# CY8C5868AXI_LP035 register map
File version: 0.1
Registers are 8-bit, read-write, no defined reset value unless marked. A register's access mark holds for its fields unless they carry their own. Offsets are from the block's base; [hi:lo] are bit positions; {n}, {i} and the like mark numbered series; 'fields as' and 'values as' point back to an identical list.

## WaveDAC8_1_VDAC8
Base 0x400043A8
0x00 VDAC8_PM_ACT_CFG — Active Power Mode Configuration Register 8
  [4:0] en_dac — Enable DAC block(s). Populated subsystems are counted from the LSB
0x10 VDAC8_PM_STBY_CFG — Standby Power Mode Configuration Register 8
  fields as VDAC8_PM_ACT_CFG
0x261 VDAC8_TR
  [7:0] tr — 8 Calibration bits
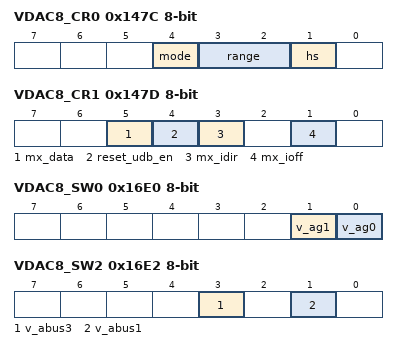
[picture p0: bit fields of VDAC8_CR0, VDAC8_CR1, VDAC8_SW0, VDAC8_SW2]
0x147C VDAC8_CR0 — DAC Block Control Register 0
  [4] mode ro — Mode Bit
    0=DAC_MODE_V (voltage DAC); 1=DAC_MODE_I (current DAC)
  [3:2] range — Ranges for mode=0 (VDAC) and mode=1 (IDAC)
    0=DAC_RANGE_0 (x0=0V to 4*vref (1.024V); 0 to 31.875uA); 1=DAC_RANGE_1 (x1=0V to 16*vref (4.096V); 0 to 255uA); 2=DAC_RANGE_2 (x0=0V to 4*vref (1.024V); 0 to 2.040mA); 3=DAC_RANGE_3 (x1=0V to 16*vref (4.096V); not used)
  [1] hs — High Speed Bit
    0=DAC_HS_LOWPOWER (regular (low power)); 1=DAC_HS_HIGHSPEED (high speed (higher power))
0x147D VDAC8_CR1 — DAC Block Control Register 1
  [5] mx_data — Select DATA source
    0=MX_DATA_REG (Select register source (DACxn_D)); 1=MX_DATA_UDB (Select UDB source)
  [4] reset_udb_en — DAC reset enable
    0=RESET_UDB_EN_DISABLE (Disable DAC Reset Source from UDB (System reset always resets)); 1=RESET_UDB_EN_ENABLE (Enable DAC Reset Source from UDB)
  [3] mx_idir — Mux selection for DAC current direction control
    0=MX_IDIR_REG (Register source idirbit selected); 1=MX_IDIR_UDB (UDB ictrl selected)
  [1] mx_ioff — Mux selection for DAC current off control
    0=MX_IOFF_REG (Register source ioffbit selected); 1=MX_IOFF_UDB (UDB ictrl selected)
0x16E0 VDAC8_SW0 — DAC Analog Routing Register 0
  [1] v_ag1 — Connect voltage output to analog global of same side
    0=AG_NC (not connected); 1=AG_CONNECTED (Connect to Analog Global)
  [0] v_ag0 — Connect voltage output to analog global of same side
    values as v_ag1
0x16E2 VDAC8_SW2 — DAC Analog Routing Register 2
  [3] v_abus3 — Connect voltage output to analog (local) bus of the same side
    0=ABUS_NC (not connected); 1=ABUS_CONNECTED (Connect to Analog (local) Bus)
  [1] v_abus1 — Connect voltage output to analog (local) bus of the same side
    values as v_abus3
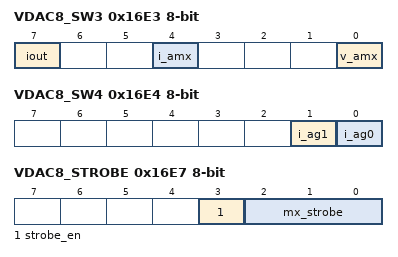
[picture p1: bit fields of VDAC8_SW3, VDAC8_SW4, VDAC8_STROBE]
0x16E3 VDAC8_SW3 — DAC Analog Routing Register 3
  [7] iout — Connect current output to pad
    0=IOUT_NC (not connected); 1=IOUT_CONNECT (Connect to pad)
  [4] i_amx — Connect current output to Analog Mux Bus
    0=AMX_NC (not connected); 1=AMX_CONNECTED (Connect to AMUXBUS)
  [0] v_amx — Connect voltage output to Analog Mux Bus
    values as i_amx
0x16E4 VDAC8_SW4 — DAC Analog Routing Register 4
  [1] i_ag1 — Connect current output to analog global of same side
    values as VDAC8_SW0.v_ag1
  [0] i_ag0 — Connect current output to analog global of same side
    values as VDAC8_SW0.v_ag1
0x16E7 VDAC8_STROBE — DAC Strobe Register
  [3] strobe_en — Strobe gating control (See mx_strobe==3'h0)
    0=disable strobe; 1=enable strobe
  [2:0] mx_strobe — Strobe source selection
    0=MX_STROBE_BUSWRITE (Select bus write strobe source (Enable gater regardless of strobe_en setting)); 1=MX_STROBE_UDB_SRC (Select UDB strobe source); 2=MX_STROBE_NC_2 (NC); 3=MX_STROBE_NC_3 (NC); {v}=MX_STROBE_CLK_A{v-4}_DIG (Select clk_a{v-4}_dig) (v=4..7)
0x17D9 VDAC8_DATA — DAC Data Register
  [7:0] data — 8 DAC Data bits

## ADC_SAR_1 — SAR ADC
Base 0x40004616
0x00 SAR_TR0 — SAR trim register
{0x12F2+i} SAR_CSR{i} (i=0..6) — SAR status and control register {i}
0x1512 SAR_SW0 — SAR Analog Routing Register 0
{0x1512+i} SAR_SW{i} (i=2..4) — SAR Analog Routing Register {i}
0x1518 SAR_SW6 — SAR Analog Routing Register 6
0x1519 SAR_CLK — SAR Clock Selection Register
0x158C SAR_WRK 16-bit — SAR working register

## SPIS_1
Base 0x40006409
0x00 SPIS_1_RX_DATA — SPIS RX Data
0x00 SPIS_1_TX_DATA — SPIS TX Data
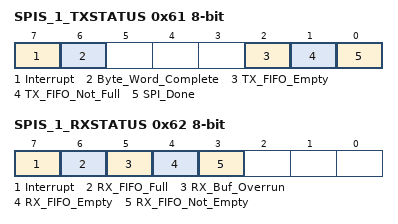
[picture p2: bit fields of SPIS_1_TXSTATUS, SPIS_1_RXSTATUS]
0x61 SPIS_1_TXSTATUS — SPIS TX Status Register
  [7] Interrupt ro — Set when interrupt occurs
  [6] Byte_Word_Complete ro — Set when a byte/word transmit has completed
  [2] TX_FIFO_Empty ro — Set when the TX Data FIFO is empty
  [1] TX_FIFO_Not_Full ro — Set when the TX Data FIFO is not full
  [0] SPI_Done ro — Set when all of the data in the transmit FIFO has been sent. Set when Byte/Word Complete has been set and TX Data FIFO is empty
0x62 SPIS_1_RXSTATUS — SPIS RX Status Register
  [7] Interrupt ro — Set when interrupt occurs
  [6] RX_FIFO_Full ro — Set when the RX Data FIFO is full
  [5] RX_Buf_Overrun ro — Set when RX Data has overrun the 4 byte/word FIFO without being moved to the RX buffer cmemory array (if one exists)
  [4] RX_FIFO_Empty ro — Set when the RX Data FIFO is empty
  [3] RX_FIFO_Not_Empty ro — Set when the RX Data FIFO is not empty. That is, at least one byte/word is in the RX FIFO
